# ESP32S3_RADIO register map
File version: 0.1.0
Registers are 32-bit, read-write, no defined reset value unless marked. A register's access mark holds for its fields unless they carry their own. Offsets are from the block's base; [hi:lo] are bit positions; <NAME> marks a mode.

## RFPLL — Analog I2C block 0x62 (RF PLL) The RF PLL's VCO and its calibration. The library reads RFPLL_VCO_WINDOW after every tune. The capacitor code is `0x62:5 | 0x62:7[2] << 8` (9 bits; the vendor clamps to 0x1ff); a higher code means a lower VCO frequency. - After `set_rf_freq_offset()` the code is a manual one: `rfpll_cap_init_cal()` tries about 10 codes on either side of the calibrated one and keeps the average of those that read in-window (*decompile* S3 `phy_rfpll.o`). - The Wi-Fi PHY's temperature tracking (`rfpll_cap_track()`, after a change of 10 temperature units by default) reruns `rfpll_cap_correct()`, so the code can move after a tune (*decompile* S3 `phy_track.o`). - Upstream esp-sdr does a manual 512-code search on the ESP32-S2 through the same fields (`0x62:1`, `0x62:2[4]`, `0x62:11[6]`, `0x62:0[7]`, and `0x62:12[3:2]` as the window indication); it does not apply it to the S3 or the C6 (*upstream* `modules/lib/esp-sdr/main/targets/esp32s2/pll.h:8-36`).
Base 0x00006200
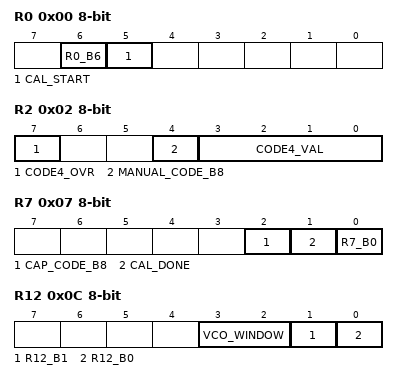
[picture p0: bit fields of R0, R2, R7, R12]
0x00 R0 8-bit — VCO calibration start Init: 0xa8, written by the vendor's PHY init `restart_cal()` starts the VCO calibration with a rising edge on bit 5 while bit 6 is toggled: it sets bit 6, pulses bit 5, clears bit 6. Bit 6 and the other bits: unknown. Evidence: *decompile* S3 `phy_rfpll.o`, S3 `phy_i2c.o`
  [6] R0_B6 — Unknown; set around the pulse on RFPLL_CAL_START.
  [5] CAL_START wo — Calibration start: a rising edge starts the VCO calibration.
0x01 R1 8-bit — Manual capacitor code, bits 7:0
  [7:0] MANUAL_CODE — `write_pll_cap()` writes the code here (`rf_test` prints it as `ir_cap_ext`). After a tune it holds the low byte of the code in use: 127 with code 383, 208 at 2412 MHz. Evidence: *decompile* S3 `phy_rfpll.o`, `rf_test.o`; *measured* bench 2026-10-09
0x02 R2 8-bit — 4-bit code override and manual capacitor code bit 8 Init: 0x88, written by the vendor's PHY init `get_rf_freq_init()` clears RFPLL_CODE4_OVR, calibrates at 2437 MHz, copies RFPLL_CODE4_CAL into RFPLL_CODE4_VAL and sets RFPLL_CODE4_OVR. What the 4-bit code controls is unknown. Evidence: *decompile* S3 `phy_hw_freq.o`, `phy_i2c.o`
  [7] CODE4_OVR — 4-bit code override: cleared before and set after the copy into RFPLL_CODE4_VAL.
  [4] MANUAL_CODE_B8 — Manual capacitor code, bit 8. Written with RFPLL_MANUAL_CODE. Evidence: *decompile* S3 `phy_rfpll.o`
  [3:0] CODE4_VAL — The 4-bit code, copied from RFPLL_CODE4_CAL.
0x05 R5 8-bit — Capacitor code readback, bits 7:0
  [7:0] CAP_CODE ro — Capacitor code readback, bits 7:0. Values: see "Measured PLL behaviour". Evidence: *decompile* S3 `phy_rfpll.o`; *measured*
0x06 R6 8-bit — Calibrated 4-bit code
  [3:0] CODE4_CAL ro — Copied into RFPLL_CODE4_VAL by the vendor. Evidence: *decompile* S3 `phy_hw_freq.o`, `phy_i2c.o` (as RFPLL_R2)
0x07 R7 8-bit — Capacitor code bit 8 and calibration done
  [2] CAP_CODE_B8 ro — Capacitor code readback, bit 8. Evidence: *decompile* S3 `phy_rfpll.o`; *measured*
  [1] CAL_DONE ro — Calibration done; 1 after every tune. `wait_rfpll_cal_end()` polls it every 20 us, 100 times, then prints `error: pll_cal exceeds 2ms!!!`. Evidence: *decompile* S3 `phy_rfpll.o`; *measured*
  [0] R7_B0 ro — Unknown; 1 in every read (RFPLL_R7 = 0x03 or 0x07). Evidence: *measured* bench 2026-10-09
0x0B R11 8-bit — Capacitor code source Init: 0x48, written by the vendor's PHY init
  [6] CODE_SRC — Cleared before each software calibration (`set_rfpll_freq()`), set by `rfpll_cap_init_cal()` before it tries manual codes. Inferred: 0 = code from the calibration engine, 1 = code from RFPLL_MANUAL_CODE and RFPLL_MANUAL_CODE_B8. Evidence: *decompile* S3 `phy_rfpll.o`
0x0C R12 8-bit — VCO window comparator and two unknown status bits Init: 0x00, read at 2412 MHz (see "Measured PLL behaviour")
  [3:2] VCO_WINDOW ro — After calibration: 0 = the VCO inside its tuning window; 1 = target below the window (code pinned at its maximum); 2 = target above it (code 0). Live for the current code: the vendor's `rfpll_cap_correct()` moves the code in steps of 2, up while it reads 1 and down while it reads 2. `esp_sdr_set_freq()` and `esp_sdr_set_freq_offset()` return -ERANGE when it is not 0. Window (PLL): 2193 to 2781 MHz. Evidence: *measured* bench 2026-10-09; *working* `lib/esp_sdr/src/esp_sdr.c:78-97, 194-196, 213-215`; *decompile* S3 `phy_rfpll.o`
  [1] R12_B1 ro — Unknown; set from about 2700 MHz (PLL) up. Evidence: *measured* bench 2026-10-09
  [0] R12_B0 ro — Unknown; always 0. Evidence: *measured* bench 2026-10-09
